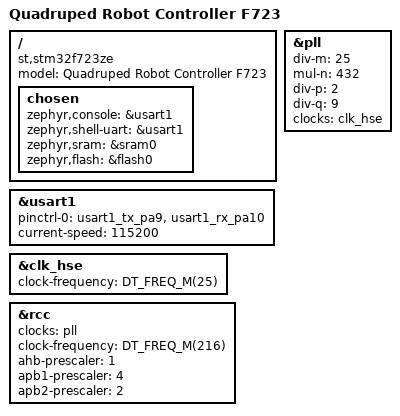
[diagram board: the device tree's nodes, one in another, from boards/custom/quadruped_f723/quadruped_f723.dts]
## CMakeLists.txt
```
cmake_minimum_required(VERSION 3.20.0)

list(APPEND BOARD_ROOT ${CMAKE_CURRENT_SOURCE_DIR})

find_package(Zephyr REQUIRED HINTS $ENV{ZEPHYR_BASE})
project(quadruped_firmware)

target_sources(app PRIVATE src/main.c)
```

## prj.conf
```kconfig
CONFIG_PRINTK=y
CONFIG_GPIO=y
CONFIG_SERIAL=y
CONFIG_CONSOLE=y
CONFIG_UART_CONSOLE=y
```

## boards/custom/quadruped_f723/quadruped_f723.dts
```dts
/dts-v1/;
#include <st/f7/stm32f723Xe.dtsi>
#include <st/f7/stm32f723i(c-e)kx-pinctrl.dtsi>

/ {
	model = "Quadruped Robot Controller F723";
	compatible = "st,stm32f723ze", "st,stm32f7";

	chosen {
		zephyr,console = &usart1;
		zephyr,shell-uart = &usart1;
		zephyr,sram = &sram0;
		zephyr,flash = &flash0;
	};
};

/* Console log USART1: PA9 (TX), PA10 (RX) */
&usart1 {
	pinctrl-0 = <&usart1_tx_pa9 &usart1_rx_pa10>;
	pinctrl-names = "default";
	current-speed = <115200>;
	status = "okay";
};

/* Cấu hình thạch anh ngoài HSE 25MHz & PLL lên 216MHz */
&clk_hse {
	clock-frequency = <DT_FREQ_M(25)>;
	status = "okay";
};

&pll {
	div-m = <25>;
	mul-n = <432>;
	div-p = <2>;
	div-q = <9>;
	clocks = <&clk_hse>;
	status = "okay";
};

&rcc {
	clocks = <&pll>;
	clock-frequency = <DT_FREQ_M(216)>;
	ahb-prescaler = <1>;
	apb1-prescaler = <4>;
	apb2-prescaler = <2>;
};
```

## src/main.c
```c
#include <zephyr/kernel.h>
#include <zephyr/sys/printk.h>

int main(void)
{
    printk("Quadruped F723 Controller Board initialized successfully!\n");

    while (1) {
        printk("System heartbeat...\n");
        k_msleep(1000);
    }

    return 0;
}
```
